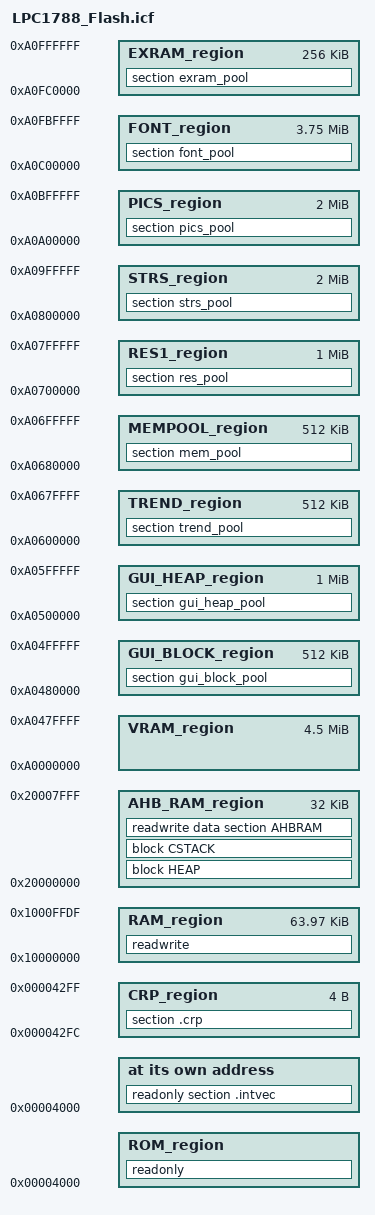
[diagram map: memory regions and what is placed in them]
/*###ICF### Section handled by ICF editor, don't touch! ****/
/*-Editor annotation file-*/
/* IcfEditorFile="$TOOLKIT_DIR$\config\ide\IcfEditor\cortex_v1_0.xml" */
/*-Specials-*/
define symbol __ICFEDIT_intvec_start__ = 0x00004000;
/*-Memory Regions-*/
define symbol __ICFEDIT_region_ROM_start__ = 0x00004000;
define symbol __ICFEDIT_region_ROM_end__   = 0x0007FFFF;
define symbol __ICFEDIT_region_RAM_start__ = 0x10000000;
define symbol __ICFEDIT_region_RAM_end__   = 0x1000FFDF;
/*-Sizes-*/
define symbol __ICFEDIT_size_cstack__ = 0x1000;
define symbol __ICFEDIT_size_heap__   = 0x3000;
/**** End of ICF editor section. ###ICF###*/

define symbol __CRP_start__   = 0x000042FC;
define symbol __CRP_end__     = 0x000042FF;

define symbol _AHB_RAM_start__  = 0x20000000;
define symbol _AHB_RAM_end__    = 0x20007FFF;

define symbol __region_VRAM_start__ =  0xA0000000;
define symbol __region_VRAM_end__    = 0xA047FFFF;

define symbol __region_GUI_BLOCK_start__  =  0xA0480000;
define symbol __region_GUI_BLOCK_end__    = 0xA04FFFFF;

define symbol __region_GUI_HEAP_start__  =  0xA0500000;
define symbol __region_GUI_HEAP_end__    = 0xA05FFFFF;

define symbol __region_TREND_start__  =  0xA0600000;
define symbol __region_TREND_end__    = 0xA067FFFF;

define symbol __region_MEMPOOL_start__ = 0xA0680000;
define symbol __region_MEMPOOL_end__   = 0xA06FFFFF;

define symbol __region_RES1_start__ = 0xA0700000;
define symbol __region_RES1_end__   = 0xA07FFFFF;

define symbol __region_STRS_LIB_start__ = 0xA0800000;
define symbol __region_STRS_LIB_end__   = 0xA09FFFFF;

define symbol __region_PICS_LIB_start__ = 0xA0A00000;
define symbol __region_PICS_LIB_end__   = 0xA0BFFFFF;

define symbol __region_FONT_LIB_start__ = 0xA0C00000;
define symbol __region_FONT_LIB_end__   = 0xA0FBFFFF;

define symbol __region_EXRAM_start__ = 0xA0FC0000;
define symbol __region_EXRAM_end__   = 0xA0FFFFFF;


define memory mem with size = 4G;
define region ROM_region   = mem:[from __ICFEDIT_region_ROM_start__   to __ICFEDIT_region_ROM_end__] - mem:[from  __CRP_start__ to __CRP_end__];
define region RAM_region   = mem:[from __ICFEDIT_region_RAM_start__   to __ICFEDIT_region_RAM_end__];
define region CRP_region   = mem:[from  __CRP_start__ to __CRP_end__];

define region AHB_RAM_region = mem:[from _AHB_RAM_start__ to _AHB_RAM_end__];
define region VRAM_region = mem:[from __region_VRAM_start__  to __region_VRAM_end__];
define region GUI_BLOCK_region = mem:[from __region_GUI_BLOCK_start__  to __region_GUI_BLOCK_end__];
define region GUI_HEAP_region = mem:[from __region_GUI_HEAP_start__  to __region_GUI_HEAP_end__];
define region TREND_region    = mem:[from __region_TREND_start__  to __region_TREND_end__];
define region MEMPOOL_region    = mem:[from __region_MEMPOOL_start__  to __region_MEMPOOL_end__];
define region RES1_region    = mem:[from __region_RES1_start__  to __region_RES1_end__];
define region STRS_region    = mem:[from __region_STRS_LIB_start__  to __region_STRS_LIB_end__];
define region PICS_region    = mem:[from __region_PICS_LIB_start__  to __region_PICS_LIB_end__];
define region FONT_region    = mem:[from __region_FONT_LIB_start__  to __region_FONT_LIB_end__];
define region EXRAM_region    = mem:[from __region_EXRAM_start__  to __region_EXRAM_end__];


define block CSTACK    with alignment = 8, size = __ICFEDIT_size_cstack__   { };
define block HEAP      with alignment = 8, size = __ICFEDIT_size_heap__     { };

initialize by copy { readwrite };
do not initialize  { section .noinit };

place at address mem:__ICFEDIT_intvec_start__ { readonly section .intvec };
place in ROM_region     { readonly };
place in RAM_region     { readwrite};
place in AHB_RAM_region { block HEAP,block CSTACK,readwrite data section AHBRAM };
place in CRP_region  	{ section .crp };

place in GUI_HEAP_region    { section gui_heap_pool };   
place in GUI_BLOCK_region   { section gui_block_pool };
place in TREND_region       { section trend_pool };
place in MEMPOOL_region     { section mem_pool };
place in RES1_region        { section res_pool };
place in STRS_region        { section strs_pool };
place in PICS_region        { section pics_pool };
place in FONT_region        { section font_pool };
place in EXRAM_region       { section exram_pool };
